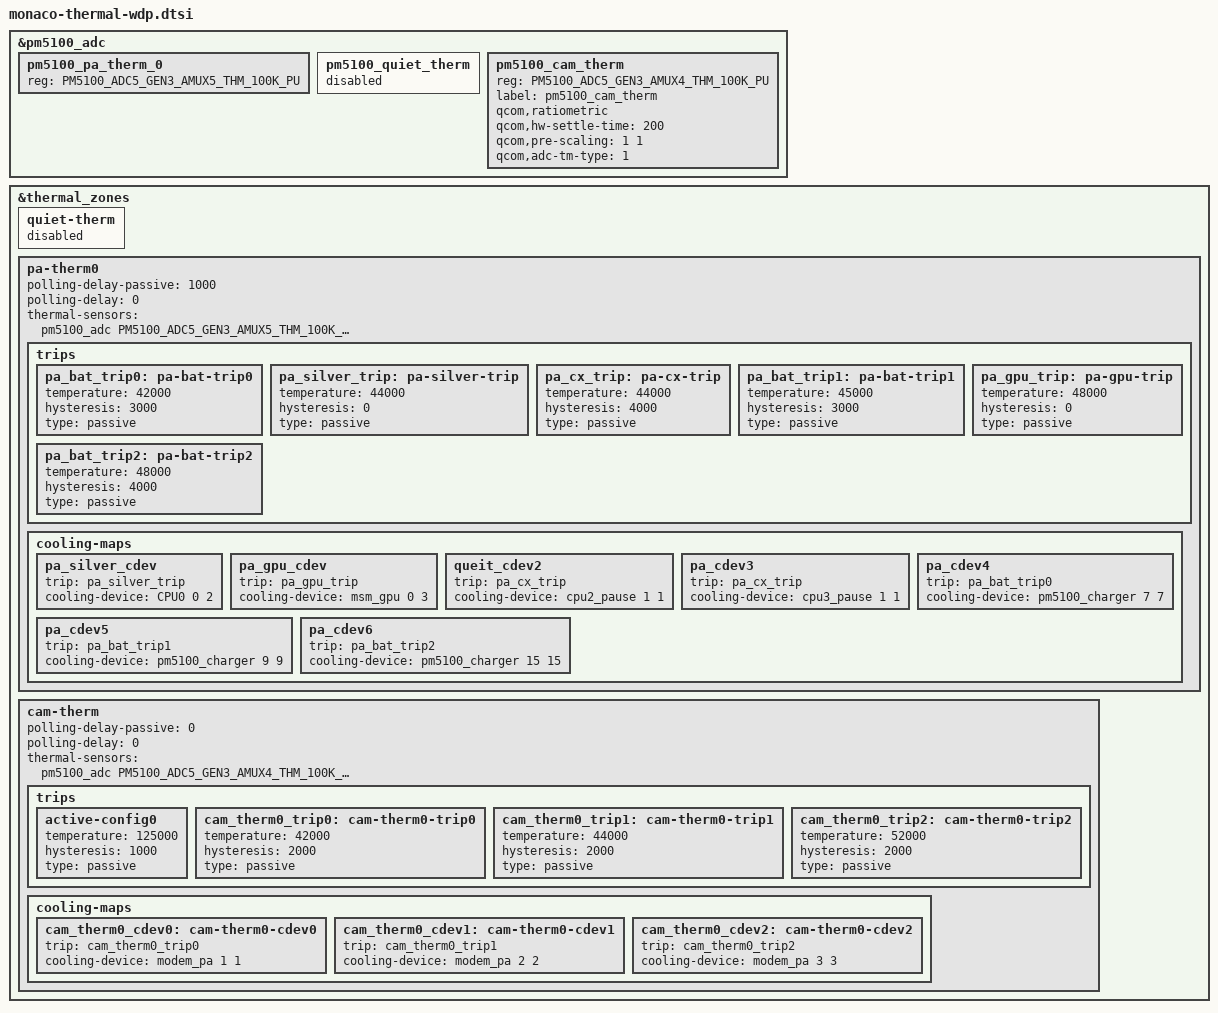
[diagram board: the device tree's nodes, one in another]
&pm5100_adc {
	pm5100_pa_therm_0 {
		reg = <PM5100_ADC5_GEN3_AMUX5_THM_100K_PU>;
	};

	pm5100_quiet_therm {
		status = "disabled";
	};

	pm5100_cam_therm {
		reg = <PM5100_ADC5_GEN3_AMUX4_THM_100K_PU>;
		label = "pm5100_cam_therm";
		qcom,ratiometric;
		qcom,hw-settle-time = <200>;
		qcom,pre-scaling = <1 1>;
		qcom,adc-tm-type = <1>;
	};
};

&thermal_zones {
	quiet-therm {
		status = "disabled";
	};

	pa-therm0 {
		polling-delay-passive = <1000>;
		polling-delay = <0>;
		thermal-sensors = <&pm5100_adc PM5100_ADC5_GEN3_AMUX5_THM_100K_PU>;
		trips {
			pa_bat_trip0: pa-bat-trip0 {
				temperature = <42000>;
				hysteresis = <3000>;
				type = "passive";
			};

			pa_silver_trip: pa-silver-trip {
				temperature = <44000>;
				hysteresis = <0>;
				type = "passive";
			};

			pa_cx_trip: pa-cx-trip {
				temperature = <44000>;
				hysteresis = <4000>;
				type = "passive";
			};

			pa_bat_trip1: pa-bat-trip1 {
				temperature = <45000>;
				hysteresis = <3000>;
				type = "passive";
			};

			pa_gpu_trip: pa-gpu-trip {
				temperature = <48000>;
				hysteresis = <0>;
				type = "passive";
			};

			pa_bat_trip2: pa-bat-trip2 {
				temperature = <48000>;
				hysteresis = <4000>;
				type = "passive";
			};
		};

		cooling-maps {
			pa_silver_cdev {
				trip = <&pa_silver_trip>;
				/* throttle to 864000KHz */
				cooling-device = <&CPU0 0 2>;
			};

			pa_gpu_cdev {
				trip = <&pa_gpu_trip>;
				/* throttle to 700000000Hz */
				cooling-device = <&msm_gpu 0 3>;
			};

			queit_cdev2 {
				trip = <&pa_cx_trip>;
				cooling-device = <&cpu2_pause 1 1>;
			};

			pa_cdev3 {
				trip = <&pa_cx_trip>;
				cooling-device = <&cpu3_pause 1 1>;
			};

			pa_cdev4 {
				trip = <&pa_bat_trip0>;
				cooling-device = <&pm5100_charger 7 7>;
			};

			pa_cdev5 {
				trip = <&pa_bat_trip1>;
				cooling-device = <&pm5100_charger 9 9>;
			};

			pa_cdev6 {
				trip = <&pa_bat_trip2>;
				cooling-device = <&pm5100_charger 15 15>;
			};
		};
	};

	cam-therm {
		polling-delay-passive = <0>;
		polling-delay = <0>;
		thermal-sensors = <&pm5100_adc PM5100_ADC5_GEN3_AMUX4_THM_100K_PU>;
		trips {
			active-config0 {
				temperature = <125000>;
				hysteresis = <1000>;
				type = "passive";
			};

			cam_therm0_trip0: cam-therm0-trip0 {
				temperature = <42000>;
				hysteresis = <2000>;
				type = "passive";
			};

			cam_therm0_trip1: cam-therm0-trip1 {
				temperature = <44000>;
				hysteresis = <2000>;
				type = "passive";
			};

			cam_therm0_trip2: cam-therm0-trip2 {
				temperature = <52000>;
				hysteresis = <2000>;
				type = "passive";
			};
		};

		cooling-maps {
			cam_therm0_cdev0:cam-therm0-cdev0 {
				trip = <&cam_therm0_trip0>;
				cooling-device = <&modem_pa 1 1>;
			};

			cam_therm0_cdev1:cam-therm0-cdev1 {
				trip = <&cam_therm0_trip1>;
				cooling-device = <&modem_pa 2 2>;
			};

			cam_therm0_cdev2:cam-therm0-cdev2 {
				trip = <&cam_therm0_trip2>;
				cooling-device = <&modem_pa 3 3>;
			};
		};
	};
};
